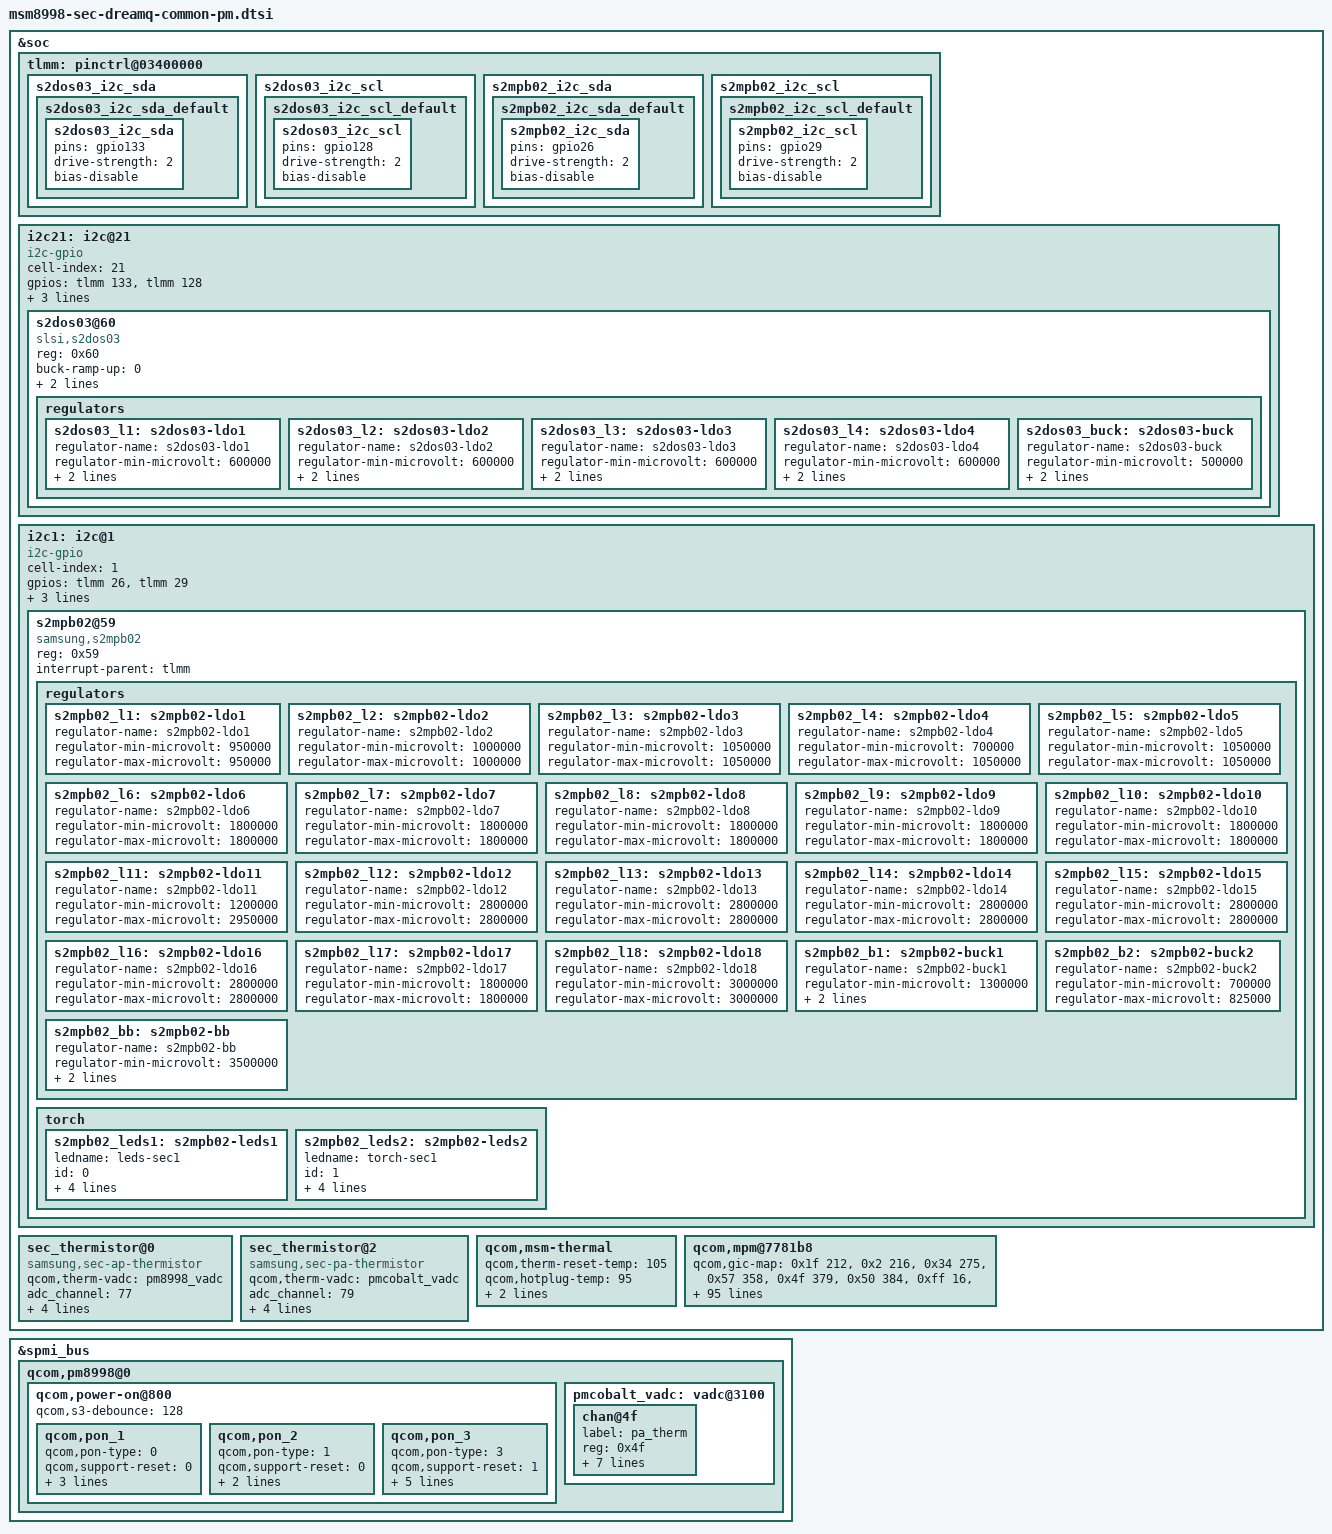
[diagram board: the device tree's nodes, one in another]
/* Copyright (c) 2014, The Linux Foundation. All rights reserved.
 *
 * This program is free software; you can redistribute it and/or modify
 * it under the terms of the GNU General Public License version 2 and
 * only version 2 as published by the Free Software Foundation.
 *
 * This program is distributed in the hope that it will be useful,
 * but WITHOUT ANY WARRANTY; without even the implied warranty of
 * MERCHANTABILITY or FITNESS FOR A PARTICULAR PURPOSE.  See the
 * GNU General Public License for more details.
 */

&soc {
	tlmm: pinctrl@03400000 {
		s2dos03_i2c_sda {
			s2dos03_i2c_sda_default: s2dos03_i2c_sda_default {
				s2dos03_i2c_sda {
					pins = "gpio133";
					drive-strength = <2>;
					bias-disable;
				};
			};
		};
		s2dos03_i2c_scl {
			s2dos03_i2c_scl_default: s2dos03_i2c_scl_default {
				s2dos03_i2c_scl {
					pins = "gpio128";
					drive-strength = <2>;
					bias-disable;
				};
			};
		};

		s2mpb02_i2c_sda {
			s2mpb02_i2c_sda_default: s2mpb02_i2c_sda_default {
				s2mpb02_i2c_sda {
					pins = "gpio26";
					drive-strength = <2>;
					bias-disable;
				};
			};
		};
		s2mpb02_i2c_scl {
			s2mpb02_i2c_scl_default: s2mpb02_i2c_scl_default {
				s2mpb02_i2c_scl {
					pins = "gpio29";
					drive-strength = <2>;
					bias-disable;
				};
			};
		};
	};

	/* S2DOS03 Display PMIC */
	i2c21: i2c@21 {
		cell-index = <21>;
		compatible = "i2c-gpio";
		gpios = <&tlmm 133 0 /* sda */
			&tlmm 128 0 /* scl */
		>;
		#i2c-gpio,delay-us = <2>;
		#address-cells = <1>;
		#size-cells = <0>;

		pinctrl-names = "s2dos03_i2c_pins_default";
		pinctrl-0 = <&s2dos03_i2c_sda_default &s2dos03_i2c_scl_default>;

		s2dos03@60 {
			compatible = "slsi,s2dos03";
			reg = <0x60>;

			buck-ramp-up = <0>;		/* 6.25mV/us */
			buck-fpwm = <0>;		/* Disable */

			uvlo-fall-threshold = <0>;	/* 2.30V */

			regulators {
				s2dos03_l1: s2dos03-ldo1 {
					regulator-name = "s2dos03-ldo1";
					regulator-min-microvolt = <600000>;
					regulator-max-microvolt = <3775000>;
					active-discharge-enable = <1>;
				};

				s2dos03_l2: s2dos03-ldo2 {
					regulator-name = "s2dos03-ldo2";
					regulator-min-microvolt = <600000>;
					regulator-max-microvolt = <3775000>;
					active-discharge-enable = <1>;
				};

				s2dos03_l3: s2dos03-ldo3 {
					regulator-name = "s2dos03-ldo3";
					regulator-min-microvolt = <600000>;
					regulator-max-microvolt = <3775000>;
					active-discharge-enable = <1>;
				};

				s2dos03_l4: s2dos03-ldo4 {
					regulator-name = "s2dos03-ldo4";
					regulator-min-microvolt = <600000>;
					regulator-max-microvolt = <3775000>;
					active-discharge-enable = <1>;
				};

				s2dos03_buck: s2dos03-buck {
					regulator-name = "s2dos03-buck";
					regulator-min-microvolt = <500000>;
					regulator-max-microvolt = <2093750>;
					active-discharge-enable = <1>;
				};
			};
		};
	};

	/* S2MPB02 Camera PMIC */
	i2c1: i2c@1 {
		cell-index = <1>;
		compatible = "i2c-gpio";
		gpios = <&tlmm 26 0
			&tlmm 29 0
		>;
		i2c-gpio,delay-us = <2>;
		#address-cells = <1>;
		#size-cells = <0>;

		pinctrl-names = "default";
		pinctrl-0 = <&s2mpb02_i2c_sda_default &s2mpb02_i2c_scl_default>;

		s2mpb02@59 {
			compatible = "samsung,s2mpb02";
			reg = <0x59>;
			interrupt-parent = <&tlmm>;
			status = "okay";

			regulators {
				s2mpb02_l1: s2mpb02-ldo1 {
					regulator-name = "s2mpb02-ldo1";
					regulator-min-microvolt = <950000>;
					regulator-max-microvolt = <950000>;
				};

				s2mpb02_l2: s2mpb02-ldo2 {
					regulator-name = "s2mpb02-ldo2";
					regulator-min-microvolt = <1000000>;
					regulator-max-microvolt = <1000000>;
				};

				s2mpb02_l3: s2mpb02-ldo3 {
					regulator-name = "s2mpb02-ldo3";
					regulator-min-microvolt = <1050000>;
					regulator-max-microvolt = <1050000>;
				};

				s2mpb02_l4: s2mpb02-ldo4 {
					regulator-name = "s2mpb02-ldo4";
					regulator-min-microvolt = <700000>;
					regulator-max-microvolt = <1050000>;
				};

				s2mpb02_l5: s2mpb02-ldo5 {
					regulator-name = "s2mpb02-ldo5";
					regulator-min-microvolt = <1050000>;
					regulator-max-microvolt = <1050000>;
				};

				s2mpb02_l6: s2mpb02-ldo6 {
					regulator-name = "s2mpb02-ldo6";
					regulator-min-microvolt = <1800000>;
					regulator-max-microvolt = <1800000>;
				};

				s2mpb02_l7: s2mpb02-ldo7 {
					regulator-name = "s2mpb02-ldo7";
					regulator-min-microvolt = <1800000>;
					regulator-max-microvolt = <1800000>;
				};

				s2mpb02_l8: s2mpb02-ldo8 {
					regulator-name = "s2mpb02-ldo8";
					regulator-min-microvolt = <1800000>;
					regulator-max-microvolt = <1800000>;
				};

				s2mpb02_l9: s2mpb02-ldo9 {
					regulator-name = "s2mpb02-ldo9";
					regulator-min-microvolt = <1800000>;
					regulator-max-microvolt = <1800000>;
				};

				s2mpb02_l10: s2mpb02-ldo10 {
					regulator-name = "s2mpb02-ldo10";
					regulator-min-microvolt = <1800000>;
					regulator-max-microvolt = <1800000>;
				};

				s2mpb02_l11: s2mpb02-ldo11 {
					regulator-name = "s2mpb02-ldo11";
					regulator-min-microvolt = <1200000>;
					regulator-max-microvolt = <2950000>;
				};

				s2mpb02_l12: s2mpb02-ldo12 {
					regulator-name = "s2mpb02-ldo12";
					regulator-min-microvolt = <2800000>;
					regulator-max-microvolt = <2800000>;
				};

				s2mpb02_l13: s2mpb02-ldo13 {
					regulator-name = "s2mpb02-ldo13";
					regulator-min-microvolt = <2800000>;
					regulator-max-microvolt = <2800000>;
				};

				s2mpb02_l14: s2mpb02-ldo14 {
					regulator-name = "s2mpb02-ldo14";
					regulator-min-microvolt = <2800000>;
					regulator-max-microvolt = <2800000>;
				};

				s2mpb02_l15: s2mpb02-ldo15 {
					regulator-name = "s2mpb02-ldo15";
					regulator-min-microvolt = <2800000>;
					regulator-max-microvolt = <2800000>;
				};

				s2mpb02_l16: s2mpb02-ldo16 {
					regulator-name = "s2mpb02-ldo16";
					regulator-min-microvolt = <2800000>;
					regulator-max-microvolt = <2800000>;
				};

				s2mpb02_l17: s2mpb02-ldo17 {
					regulator-name = "s2mpb02-ldo17";
					regulator-min-microvolt = <1800000>;
					regulator-max-microvolt = <1800000>;
				};

				s2mpb02_l18: s2mpb02-ldo18 {
					regulator-name = "s2mpb02-ldo18";
					regulator-min-microvolt = <3000000>;
					regulator-max-microvolt = <3000000>;
				};

				s2mpb02_b1: s2mpb02-buck1 {
					regulator-name = "s2mpb02-buck1";
					regulator-min-microvolt = <1300000>;
					regulator-max-microvolt = <1300000>;
					regulator-always-on;
				};

				s2mpb02_b2: s2mpb02-buck2 {
					regulator-name = "s2mpb02-buck2";
					regulator-min-microvolt = <700000>;
					regulator-max-microvolt = <825000>;
				};

				s2mpb02_bb: s2mpb02-bb {
					regulator-name = "s2mpb02-bb";
					regulator-min-microvolt = <3500000>;
					regulator-max-microvolt = <3500000>;
					regulator-always-on;
				};
			};

			torch {
				status = "okay";
				s2mpb02_leds1: s2mpb02-leds1 {
					ledname = "leds-sec1";
					/* S2MPB02_FLASH_LED_1 */
					id = <0>;
					/* S2MPB02_FLASH_CURRENT */
					brightness = <0xA>;
					/* S2MPB02_FLASH_TIMEOUT */
					timeout = <0x7>;
					default-trigger = "flash_trigger";
					gpios = <&tlmm 22 0>;
				};

				s2mpb02_leds2: s2mpb02-leds2 {
					ledname = "torch-sec1";
					/* S2MPB02_TORCH_LED_1 */
					id = <1>;
					/* S2MPB02_TORCH_CURRENT */
					brightness = <0x9>;
					/* S2MPB02_TORCH_TIMEOUT */
					timeout = <0xF>;
					default-trigger = "torch_trigger";
					gpios = <&tlmm 21 0>;
				};
			};
		};
	};

	/* Thermistor table */
	sec_thermistor@0 {
		compatible = "samsung,sec-ap-thermistor";
		qcom,therm-vadc = <&pm8998_vadc>;
		status = "okay";
		adc_channel = <77>;
		adc_array = <1002 1039 1076 1112 1149 1186 1236 1286 1335 1385
				  	 1435 1487 1540 1592 1645 1697 1760 1823 1886 1949
					 2012 2085 2157 2230 2302 2375 2482 2589 2696 2803
					 2910 3035 3159 3284 3408 3533 3649 3765 3881 3997
					 4113 4246 4379 4513 4646 4779 4928 5077 5227 5376
					 5525 5691 5857 6023 6189 6355 6528 6700 6873 7045
					 7218 7398 7578 7757 7937 8117 8305 8492 8680 8867
					 9055 9224 9392 9561 9729 9898 10092 10287 10481 10676
					 10870 11035 11200 11365 11530 11695 11859 12024 12188 12353
					 12517 12656 12795 12935 13074 13213 13341 13469 13596 13724
					 13852 13962 14071 14181 14290 14400 14490 14580 14670 14760
					 14850>;

		temp_array = <900 890 880 870 860 850 840 830 820 810
				800 790 780 770 760 750 740 730 720 710
				700 690 680 670 660 650 640 630 620 610
				600 590 580 570 560 550 540 530 520 510
				500 490 480 470 460 450 440 430 420 410
				400 390 380 370 360 350 340 330 320 310
				300 290 280 270 260 250 240 230 220 210
				200 190 180 170 160 150 140 130 120 110
				100 90 80 70 60 50 40 30 20 10
				0
				(-10) (-20) (-30) (-40) (-50) (-60) (-70) (-80) (-90) (-100)
				(-110)(-120)(-130)(-140)(-150)(-160)(-170)(-180)(-190) (-200)>;
	};

	/* PA Thermistor table */
	sec_thermistor@2 {
		compatible = "samsung,sec-pa-thermistor";
		qcom,therm-vadc = <&pmcobalt_vadc>;
		status = "okay";
		adc_channel = <79>;
		adc_array = <1002 1039 1076 1112 1149 1186 1236 1286 1335 1385
				  	 1435 1487 1540 1592 1645 1697 1760 1823 1886 1949
					 2012 2085 2157 2230 2302 2375 2482 2589 2696 2803
					 2910 3035 3159 3284 3408 3533 3649 3765 3881 3997
					 4113 4246 4379 4513 4646 4779 4928 5077 5227 5376
					 5525 5691 5857 6023 6189 6355 6528 6700 6873 7045
					 7218 7398 7578 7757 7937 8117 8305 8492 8680 8867
					 9055 9224 9392 9561 9729 9898 10092 10287 10481 10676
					 10870 11035 11200 11365 11530 11695 11859 12024 12188 12353
					 12517 12656 12795 12935 13074 13213 13341 13469 13596 13724
					 13852 13962 14071 14181 14290 14400 14490 14580 14670 14760
					 14850>;

		temp_array = <900 890 880 870 860 850 840 830 820 810
				800 790 780 770 760 750 740 730 720 710
				700 690 680 670 660 650 640 630 620 610
				600 590 580 570 560 550 540 530 520 510
				500 490 480 470 460 450 440 430 420 410
				400 390 380 370 360 350 340 330 320 310
				300 290 280 270 260 250 240 230 220 210
				200 190 180 170 160 150 140 130 120 110
				100 90 80 70 60 50 40 30 20 10
				0
				(-10) (-20) (-30) (-40) (-50) (-60) (-70) (-80) (-90) (-100)
				(-110)(-120)(-130)(-140)(-150)(-160)(-170)(-180)(-190) (-200)>;
	};

	qcom,msm-thermal {
		qcom,therm-reset-temp = <105>;
		qcom,hotplug-temp = <95>;
		sec,therm-reset-temp-offset = <10>;
		sec,hotplug-temp-offset = <10>;
	};

	qcom,mpm@7781b8 {
			qcom,gic-map =
			<0x1f 212>, /* usb30_power_event_irq	*/
			<0x2 216>, /* tsens1_upper_lower_int	*/
			<0x34 275>, /* qmp_usb3_lfps_rxterm_irq_cx	*/
			<0x57 358>, /*  spmi_periph_irq[0]	*/
			<0x4f 379>, /* usb2phy_intr	*/
			<0x50 384>, /* sp_rmb_sp2soc_irq	*/
			<0xff 16>, /* APC0_qgicQTmrHypPhysIrptReq	*/
			<0xff 17>, /* APC3_qgicQTmrSecPhysIrptReq	*/
			<0xff 18>, /* APC0_qgicQTmrNonSecPhysIrptReq	*/
			<0xff 19>, /* APC3_qgicQTmrVirtIrptReq	*/
			<0xff 20>, /* APC0_dbgCommRxFull	*/
			<0xff 21>, /* APC3_dbgCommTxEmpty	*/
			<0xff 22>, /* APC0_qgicPerfMonIrptReq	*/
			<0xff 23>, /* corespm_vote_int[7]	*/
			<0xff 24>, /* APC0_qgicExtFaultIrptReq	*/
			<0xff 28>, /* qgicWakeupSync	*/
			<0xff 29>, /* APCC_cti_SPI_intx	*/
			<0xff 30>, /* APCC_cti_SPI_inty	*/
			<0xff 32>, /* l2spm_vote_int[0]	*/
			<0xff 33>, /* l2spm_vote_int[1]	*/
			<0xff 34>, /* APCC_qgicL2ErrorIrptReq	*/
			<0xff 35>, /* WDT_barkInt	*/
			<0xff 36>, /* WDT_biteExpired	*/
			<0xff 39>, /* QTMR_qgicFrm0VirtIrq	*/
			<0xff 40>, /* QTMR_qgicFrm0PhyIrq	*/
			<0xff 41>, /* QTMR_qgicFrm1PhyIrq	*/
			<0xff 42>, /* QTMR_qgicFrm2PhyIrq	*/
			<0xff 43>, /* QTMR_qgicFrm3PhyIrq	*/
			<0xff 44>, /* QTMR_qgicFrm4PhyIrq	*/
			<0xff 45>, /* QTMR_qgicFrm5PhyIrq	*/
			<0xff 46>, /* QTMR_qgicFrm6PhyIrq	*/
			<0xff 47>, /* rbif_Irq[0]	*/
			<0xff 48>, /* rbif_Irq[1]	*/
			<0xff 52>, /* cci_spm_vote_summary_int	*/
			<0xff 54>, /* ~nERRORIRQ	*/
			<0xff 55>, /* nEVNTCNTOVERFLOW_cci	*/
			<0xff 56>, /* QTMR_qgicFrm0VirtIrq	*/
			<0xff 57>, /* QTMR_qgicFrm0PhyIrq	*/
			<0xff 58>, /* QTMR_qgicFrm1PhyIrq	*/
			<0xff 59>, /* QTMR_qgicFrm2PhyIrq	*/
			<0xff 60>, /* QTMR_qgicFrm3PhyIrq	*/
			<0xff 61>, /* QTMR_qgicFrm4PhyIrq	*/
			<0xff 62>, /* QTMR_qgicFrm5PhyIrq	*/
			<0xff 63>, /* QTMR_qgicFrm6PhyIrq	*/
			<0xff 64>, /* wakeup_counter_irq_OR	*/
			<0xff 65>, /* apc0_vs_alarm	*/
			<0xff 66>, /* apc1_vs_alarm	*/
			<0xff 67>, /* o_pwr_osm_irq	*/
			<0xff 68>, /* o_perf_osm_irq	*/
			<0xff 69>, /* o_pwr_dcvsh_interrupt	*/
			<0xff 70>, /* o_perf_dcvsh_interrupt	*/
			<0xff 73>, /* L2_EXTERRIRQ_C0	*/
			<0xff 74>, /* L2_EXTERRIRQ_C1	*/
			<0xff 75>, /* L2_INTERRIRQ_C0	*/
			<0xff 76>, /* L2_INTERRIRQ_C1	*/
			<0xff 77>, /* L2SPM_svicInt[0]	*/
			<0xff 78>, /* L2SPM_svicInt[1]	*/
			<0xff 79>, /* L2SPM_svicIntSwDone[0]	*/
			<0xff 80>, /* L2SPM_svicIntSwDone[1]	*/
			<0xff 81>, /* l2_avs_err[0]	*/
			<0xff 82>, /* l2_avs_err[1]	*/
			<0xff 83>, /* l2_avs_ack[0]	*/
			<0xff 84>, /* l2_avs_ack[1]	*/
			<0xff 96>, /* uart_dm_intr	*/
			<0xff 97>, /* uart_dm_intr	*/
			<0xff 98>, /* o_qm_interrupt	*/
			<0xff 100>, /* jpeg_vbif_irpt	*/
			<0xff 101>, /* processor_1_user_int	*/
			<0xff 102>, /* processor_1_kernel_int	*/
			<0xff 106>, /* dir_conn_irq_lpa_dsp_2	*/
			<0xff 107>, /* dir_conn_irq_lpa_dsp_1	*/
			<0xff 109>, /* camss_vbif_0_irq	*/
			<0xff 110>, /* csiphy_irq	*/
			<0xff 111>, /* csiphy_irq	*/
			<0xff 112>, /* csiphy_irq	*/
			<0xff 115>, /* mdp_irq	*/
			<0xff 116>, /* vbif_irpt	*/
			<0xff 117>, /* dir_conn_irq_lpa_dsp_0	*/
			<0xff 119>, /* lcc_audio_wrapper_q6	*/
			<0xff 122>, /* PIMEM TPDM BC interrupt	*/
			<0xff 123>, /* PIMEM TPDM TC interrupt	*/
			<0xff 124>, /* dir_conn_irq_sensors_1	*/
			<0xff 125>, /* dir_conn_irq_sensors_0	*/
			<0xff 126>, /* qup_irq	*/
			<0xff 127>, /* qup_irq	*/
			<0xff 128>, /* qup_irq	*/
			<0xff 129>, /* qup_irq	*/
			<0xff 130>, /* qup_irq	*/
			<0xff 131>, /* qup_irq	*/
			<0xff 132>, /* qup_irq	*/
			<0xff 133>, /* qup_irq	*/
			<0xff 134>, /* qup_irq	*/
			<0xff 135>, /* qup_irq	*/
			<0xff 136>, /* qup_irq	*/
			<0xff 137>, /* qup_irq	*/
			<0xff 138>, /* qup_irq	*/
			<0xff 139>, /* uart_dm_intr	*/
			<0xff 140>, /* uart_dm_intr	*/
			<0xff 141>, /* uart_dm_intr	*/
			<0xff 145>, /* uart_dm_intr	*/
			<0xff 146>, /* uart_dm_intr	*/
			<0xff 147>, /* uart_dm_intr	*/
			<0xff 148>, /* osmmu_Cirpt[4]	*/
			<0xff 149>, /* osmmu_Cirpt[5]	*/
			<0xff 151>, /* tsif_irq[0]	*/
			<0xff 152>, /* tsif_irq[1]	*/
			<0xff 153>, /* tspp_irq	*/
			<0xff 154>, /* bam_irq	*/
			<0xff 155>, /* dir_conn_irq_lpa_dsp_5	*/
			<0xff 156>, /* dir_conn_irq_lpa_dsp_4	*/
			<0xff 157>, /* sdcc_irq	*/
			<0xff 158>, /* sdcc_irq	*/
			<0xff 159>, /* lpass_qos_apps_interrupt	*/
			<0xff 160>, /* smmu_PMIrpt	*/
			<0xff 161>, /* sdcc_irq	*/
			<0xff 162>, /* sdcc_irq	*/
			<0xff 163>, /* usb30_ctrl_irq[0]	*/
			<0xff 164>, /* usb30_bam_irq	*/
			<0xff 165>, /* usb30_hs_phy_irq	*/
			<0xff 166>, /* o_lm_int_2qgic	*/
			<0xff 167>, /* pcie20_inta	*/
			<0xff 168>, /* pcie20_intb	*/
			<0xff 169>, /* smmu_Cirpt[12]	*/
			<0xff 170>, /* pcie20_intc	*/
			<0xff 171>, /* pcie20_intd	*/
			<0xff 172>, /* dcvs_int(8)	*/
			<0xff 173>, /* dcvs_int(9)	*/
			<0xff 184>, /* dir_conn_irq_lpa_dsp_3	*/
			<0xff 185>, /* camss_vbif_2_irq	*/
			<0xff 186>, /* mnoc_obs_mainFault	*/
			<0xff 188>, /* q6ss_irq_out(4)	*/
			<0xff 189>, /* q6ss_irq_out(5)	*/
			<0xff 190>, /* q6ss_irq_out(6)	*/
			<0xff 191>, /* q6ss_irq_out(7)	*/
			<0xff 192>, /* audio_out0_irq	*/
			<0xff 194>, /* q6ss_wdog_exp_irq	*/
			<0xff 195>, /* lpass_slimbus_core_ee1_irq	*/
			<0xff 196>, /* lpass_slimbus_bam_ee1_irq	*/
			<0xff 197>, /* resampler_irq[0]	*/
			<0xff 199>, /* qdss_usb_trace_bam_irq	*/
			<0xff 200>, /* rpm_ipc[4]	*/
			<0xff 201>, /* rpm_ipc[5]	*/
			<0xff 202>, /* rpm_ipc[6]	*/
			<0xff 203>, /* rpm_ipc[7]	*/
			<0xff 204>, /* rpm_ipc[20]	*/
			<0xff 205>, /* rpm_ipc[21]	*/
			<0xff 206>, /* rpm_ipc[22]	*/
			<0xff 207>, /* rpm_ipc[23]	*/
			<0xff 208>, /* q6ss_irq_out(4)	*/
			<0xff 209>, /* q6ss_irq_out(5)	*/
			<0xff 210>, /* q6ss_irq_out(6)	*/
			<0xff 211>, /* q6ss_irq_out(7)	*/
			<0xff 213>, /* secure_wdog_bark_irq	*/
			<0xff 214>, /* tsens1_tsens_max_min_int	*/
			<0xff 215>, /* o_bimc_intr[0]	*/
			<0xff 217>, /* ocimem_nonsec_irq	*/
			<0xff 218>, /* sscaon_tmr_timeout_irq	*/
			<0xff 219>, /* q6ss_irq_out(28)	*/
			<0xff 220>, /* spmi_protocol_irq	*/
			<0xff 221>, /* q6ss_irq_out(29)	*/
			<0xff 222>, /* q6ss_irq_out(30)	*/
			<0xff 223>, /* spdm_offline_irq	*/
			<0xff 224>, /* spdm_realtime_irq	*/
			<0xff 225>, /* snoc_obs_mainFault	*/
			<0xff 226>, /* cnoc_obs_mainFault	*/
			<0xff 227>, /* o_ss_xpu3_sec_intr	*/
			<0xff 228>, /* o_tcsr_xpu3_non_sec_summary_intr	*/
			<0xff 229>, /* o_timeout_slave_kpss_summary_intr */
			<0xff 230>, /* o_tcsr_vmidmt_client_sec_summary_intr */
			<0xff 231>, /* o_tcsr_vmidmt_client_non_sec */
			<0xff 232>, /* o_tcsr_vmidmt_cfg_sec_summary_intr */
			<0xff 233>, /* o_tcsr_vmidmt_cfg_non_sec */
			<0xff 234>, /* q6ss_irq_out(31)	*/
			<0xff 235>, /* cpr_irq[0]	*/
			<0xff 236>, /* crypto_core_irq[0]	*/
			<0xff 237>, /* crypto_core_irq[1]	*/
			<0xff 238>, /* crypto_bam_irq[0]	*/
			<0xff 239>, /* crypto_bam_irq[1]	*/
			<0xff 240>, /* summary_irq_hmss	*/
			<0xff 241>, /* dir_conn_irq_hmss_7	*/
			<0xff 242>, /* dir_conn_irq_hmss_6	*/
			<0xff 243>, /* dir_conn_irq_hmss_5	*/
			<0xff 244>, /* dir_conn_irq_hmss_4	*/
			<0xff 245>, /* dir_conn_irq_hmss_3	*/
			<0xff 246>, /* dir_conn_irq_hmss_2	*/
			<0xff 247>, /* dir_conn_irq_hmss_1	*/
			<0xff 248>, /* dir_conn_irq_hmss_0	*/
			<0xff 249>, /* summary_irq_hmss_tz	*/
			<0xff 250>, /* cpr_irq[3]	*/
			<0xff 251>, /* cpr_irq[2]	*/
			<0xff 252>, /* cpr_irq[1]	*/
			<0xff 253>, /* sdcc_pwr_cmd_irq	*/
			<0xff 254>, /* sdio_wakeup_irq	*/
			<0xff 255>, /* cpr_irq[0]	*/
			<0xff 256>, /* smmu_Cirpt[13]	*/
			<0xff 257>, /* smmu_Cirpt[14]	*/
			<0xff 258>, /* smmu_Cirpt[0]	*/
			<0xff 259>, /* sdcc_pwr_cmd_irq	*/
			<0xff 260>, /* sdio_wakeup_irq	*/
			<0xff 261>, /* o_tcsr_mmu_nsgcfglrpt_summary_intr */
			<0xff 262>, /* o_tcsr_mmu_gcfglrpt_summary_intr	*/
			<0xff 263>, /* o_tcsr_mmu_nsglrpt_summary_intr	*/
			<0xff 264>, /* o_tcsr_mmu_glrpt_summary_intr	*/
			<0xff 265>, /* vbif_irpt	*/
			<0xff 266>, /* smmu_PMIrpt	*/
			<0xff 267>, /* smmu_Cirpt[3]	*/
			<0xff 268>, /* q6ss_irq_out(31)	*/
			<0xff 269>, /* rpm_wdog_expired_irq	*/
			<0xff 270>, /* bam_irq	*/
			<0xff 271>, /* bam_irq	*/
			<0xff 272>, /* q6ss_irq_out(28)	*/
			<0xff 273>, /* q6ss_irq_out(29)	*/
			<0xff 274>, /* q6ss_irq_out(30)	*/
			<0xff 276>, /* osmmu_Cirpt [4]	*/
			<0xff 277>, /* osmmu_Cirpt [5]	*/
			<0xff 278>, /* usb30_ctrl_irq[1]	*/
			<0xff 279>, /* osmmu_Cirpt [6]	*/
			<0xff 280>, /* osmmu_Cirpt [7]	*/
			<0xff 281>, /* osmmu_Cirpt [8]	*/
			<0xff 282>, /* osmmu_Cirpt [9]	*/
			<0xff 283>, /* osmmu_Cirpt [10]	*/
			<0xff 284>, /* osmmu_Cirpt [11]	*/
			<0xff 285>, /* osmmu_Cirpt [12]	*/
			<0xff 286>, /* osmmu_Cirpt [13]	*/
			<0xff 287>, /* osmmu_Cirpt [14]	*/
			<0xff 288>, /* osmmu_Cirpt [15]	*/
			<0xff 289>, /* ufs_ice_sec_level_irq	*/
			<0xff 290>, /* cpr_irq[4]	*/
			<0xff 291>, /* smmu_Cirpt[2]	*/
			<0xff 292>, /* osmmu_Cirpt [16]	*/
			<0xff 293>, /* osmmu_Cirpt [17]	*/
			<0xff 294>, /* osmmu_Cirpt [18]	*/
			<0xff 295>, /* osmmu_Cirpt [0]	*/
			<0xff 296>, /* osmmu_PMIrpt	*/
			<0xff 297>, /* ufs_intrq	*/
			<0xff 298>, /* osmmu_Cirpt [1]	*/
			<0xff 299>, /* osmmu_Cirpt [2]	*/
			<0xff 300>, /* osmmu_Cirpt [3]	*/
			<0xff 301>, /* smmu_Cirpt[1]	*/
			<0xff 302>, /* qdss_etrbytecnt_irq	*/
			<0xff 303>, /* smmu_Cirpt[0]	*/
			<0xff 304>, /* osmmu_Cirpt [19]	*/
			<0xff 305>, /* osmmu_Cirpt [20]	*/
			<0xff 306>, /* osmmu_Cirpt [21]	*/
			<0xff 307>, /* osmmu_Cirpt [22]	*/
			<0xff 308>, /* osmmu_Cirpt [23]	*/
			<0xff 310>, /* pcie20_global_int	*/
			<0xff 311>, /* pcie20_int_edma_int	*/
			<0xff 316>, /* lpass_hdmitx_interrupt_ext	*/
			<0xff 317>, /* rbif_irq	*/
			<0xff 318>, /* gpu_cc_gpu_cx_gds_hw_ctrl_irq_out */
			<0xff 319>, /* VENUS_IRQ	*/
			<0xff 323>, /* lpass_slimbus1_core_ee1_irq	*/
			<0xff 324>, /* lpass_slimbus1_bam_ee1_irq	*/
			<0xff 325>, /* camss_irq18	*/
			<0xff 326>, /* camss_irq0	*/
			<0xff 327>, /* camss_irq1	*/
			<0xff 328>, /* camss_irq2	*/
			<0xff 329>, /* camss_irq3	*/
			<0xff 330>, /* camss_irq4	*/
			<0xff 331>, /* camss_irq5	*/
			<0xff 332>, /* GC_SYS_irq_0	*/
			<0xff 333>, /* GC_SYS_irq_1	*/
			<0xff 334>, /* GC_SYS_irq_2	*/
			<0xff 335>, /* GC_SYS_irq_3	*/
			<0xff 336>, /* camss_irq13	*/
			<0xff 337>, /* camss_irq14	*/
			<0xff 338>, /* camss_irq15	*/
			<0xff 339>, /* camss_irq16	*/
			<0xff 340>, /* camss_irq17	*/
			<0xff 341>, /* camss_irq6	*/
			<0xff 342>, /* smmu_Cirpt[15]	*/
			<0xff 343>, /* bam_irq[0]	*/
			<0xff 344>, /* uart_dm_intr	*/
			<0xff 345>, /* camss_irq7	*/
			<0xff 346>, /* camss_irq8	*/
			<0xff 347>, /* camss_irq9	*/
			<0xff 348>, /* camss_irq10	*/
			<0xff 350>, /* camss_irq12	*/
			<0xff 351>, /* sif_aud_dec_out_irq_ext	*/
			<0xff 356>, /* vbif_nrt_irpt	*/
			<0xff 357>, /* Nonfatal pIMEM interrupt	*/
			<0xff 359>, /* spmi_periph_irq[1]	*/
			<0xff 360>, /* fatal pIMEM interrupt	*/
			<0xff 361>, /* osmmu_Cirpt[0]	*/
			<0xff 362>, /* osmmu_Cirpt[1]	*/
			<0xff 363>, /* osmmu_Cirpt[2]	*/
			<0xff 364>, /* osmmu_Cirpt[3]	*/
			<0xff 365>, /* ipa_irq(0)	*/
			<0xff 366>, /* osmmu_PMIrpt	*/
			<0xff 380>, /* sp_sp2apps_irq[0]	*/
			<0xff 381>, /* sp_sp2apps_irq[1]	*/
			<0xff 382>, /* sp_sp2apps_irq[2]	*/
			<0xff 383>, /* sp_sp2apps_irq[3]	*/
			<0xff 385>, /* osmmu_CIrpt[12]	*/
			<0xff 386>, /* osmmu_CIrpt[13]	*/
			<0xff 387>, /* osmmu_CIrpt[14]	*/
			<0xff 388>, /* osmmu_CIrpt[15]	*/
			<0xff 389>, /* osmmu_CIrpt[16]	*/
			<0xff 390>, /* osmmu_CIrpt[17]	*/
			<0xff 391>, /* osmmu_CIrpt[18]	*/
			<0xff 392>, /* osmmu_CIrpt[19]	*/
			<0xff 393>, /* o_dcc_crc_fail_int	*/
			<0xff 395>, /* aggre1_obs_mainfault	*/
			<0xff 396>, /* aggr1_smmu_cirpt[0]	*/
			<0xff 397>, /* aggr1_smmu_cirpt[1]	*/
			<0xff 398>, /* aggr1_smmu_cirpt[2]	*/
			<0xff 399>, /* aggr1_smmu_cirpt[3]	*/
			<0xff 400>, /* aggr1_smmu_cirpt[4]	*/
			<0xff 401>, /* aggr1_smmu_cirpt[5]	*/
			<0xff 402>, /* aggr1_smmu_cirpt[6]	*/
			<0xff 403>, /* aggr1_smmu_pmirpt	*/
			<0xff 404>, /* aggre2noc_obs_mainFault	*/
			<0xff 405>, /* osmmu_CIrpt[0]	*/
			<0xff 406>, /* osmmu_CIrpt[1]	*/
			<0xff 407>, /* osmmu_CIrpt[2]	*/
			<0xff 408>, /* osmmu_CIrpt[3]	*/
			<0xff 409>, /* osmmu_CIrpt[4]	*/
			<0xff 410>, /* osmmu_CIrpt[5]	*/
			<0xff 411>, /* o_dcc_task_done_int	*/
			<0xff 412>, /* vsense_alarm_irq	*/
			<0xff 413>, /* osmmu_PMIrpt	*/
			<0xff 414>, /* pmic_arb_trans_done_irq[0]	*/
			<0xff 415>, /* pmic_arb_trans_done_irq[1]	*/
			<0xff 416>, /* rpm_ipc[28]	*/
			<0xff 417>, /* rpm_ipc[29]	*/
			<0xff 418>, /* rpm_ipc[30]	*/
			<0xff 419>, /* rpm_ipc[31]	*/
			<0xff 420>, /* qup_irq	*/
			<0xff 421>, /* qup_irq	*/
			<0xff 422>, /* wd_bite_apps	*/
			<0xff 423>, /* lpass_qos_apps_interrupt	*/
			<0xff 424>, /* ipa_irq(2)	*/
			<0xff 425>, /* smmu_Cirpt[1]	*/
			<0xff 426>, /* smmu_Cirpt[2]	*/
			<0xff 427>, /* smmu_Cirpt[3]	*/
			<0xff 428>, /* smmu_Cirpt[4]	*/
			<0xff 429>, /* smmu_Cirpt[5]	*/
			<0xff 430>, /* smmu_Cirpt[6]	*/
			<0xff 431>, /* smmu_Cirpt[7]	*/
			<0xff 432>, /* smmu_Cirpt[8]	*/
			<0xff 433>, /* smmu_Cirpt[9]	*/
			<0xff 434>, /* smmu_Cirpt[10]	*/
			<0xff 435>, /* smmu_Cirpt[11]	*/
			<0xff 436>, /* smmu_Cirpt[16]	*/
			<0xff 437>, /* pcie20_0_int_msi_dev0	*/
			<0xff 438>, /* pcie20_0_int_msi_dev1	*/
			<0xff 439>, /* pcie20_0_int_msi_dev2	*/
			<0xff 440>, /* pcie20_0_int_msi_dev3	*/
			<0xff 441>, /* pcie20_0_int_msi_dev4	*/
			<0xff 442>, /* pcie20_0_int_msi_dev5	*/
			<0xff 443>, /* pcie20_0_int_msi_dev6	*/
			<0xff 444>, /* pcie20_0_int_msi_dev7	*/
			<0xff 445>, /* o_wcss_apps_intr[0]	*/
			<0xff 446>, /* o_wcss_apps_intr[1]	*/
			<0xff 447>, /* o_wcss_apps_intr[2]	*/
			<0xff 448>, /* o_wcss_apps_intr[3]	*/
			<0xff 449>, /* o_wcss_apps_intr[4]	*/
			<0xff 450>, /* o_wcss_apps_intr[5]	*/
			<0xff 452>, /* o_wcss_apps_intr[6]	*/
			<0xff 453>, /* o_wcss_apps_intr[7]	*/
			<0xff 454>, /* o_wcss_apps_intr[8]	*/
			<0xff 455>, /* o_wcss_apps_intr[9]	*/
			<0xff 456>, /* o_wcss_apps_intr[10]	*/
			<0xff 457>, /* o_wcss_apps_intr[11]	*/
			<0xff 458>, /* o_wcss_apps_intr[12]	*/
			<0xff 461>, /* o_ocimem_nonsec_irq	*/
			<0xff 462>, /* tsens1_tsens_critical_int	*/
			<0xff 463>, /* aggr1_smmu_cirpt[7]	*/
			<0xff 464>, /* ipa_bam_irq(0)	*/
			<0xff 465>, /* ipa_bam_irq(2)	*/
			<0xff 466>, /* ssc_uart_int	*/
			<0xff 468>, /* cri_cm_irq_tz	*/
			<0xff 469>, /* cri_cm_irq_hyp	*/
			<0xff 471>, /* mmss_bimc_smmu_gds_hw_ctrl_irq_out */
			<0xff 472>, /* gcc_gds_hw_ctrl_irq_out	*/
			<0xff 473>, /* lcc_audio_core_smmu_gds_hw_ctrl */
			<0xff 477>, /* tsens0_tsens_critical_int	*/
			<0xff 478>, /* tsens0_tsens_max_min_int	*/
			<0xff 480>, /* q6ss_wdog_expired_irq	*/
			<0xff 481>, /* mss_ipc_out_irq[4]	*/
			<0xff 482>, /* mss_ipc_out_irq[5]	*/
			<0xff 483>, /* mss_ipc_out_irq[6]	*/
			<0xff 484>, /* mss_ipc_out_irq[7]	*/
			<0xff 485>, /* mss_ipc_out_irq[28]	*/
			<0xff 486>, /* mss_ipc_out_irq[29]	*/
			<0xff 487>, /* mss_ipc_out_irq[30]	*/
			<0xff 488>, /* mss_ipc_out_irq[31]	*/
			<0xff 489>, /* skl_core_irq	*/
			<0xff 490>, /* tsens0_upper_lower_int	*/
			<0xff 494>, /* osmmu_CIrpt[6]	*/
			<0xff 495>, /* osmmu_CIrpt[7]	*/
			<0xff 496>, /* osmmu_CIrpt[8]	*/
			<0xff 497>, /* osmmu_CIrpt[9]	*/
			<0xff 498>, /* osmmu_CIrpt[10]	*/
			<0xff 499>, /* osmmu_CIrpt[11]	*/
			<0xff 503>, /* o_bimc_intr[1]	*/
			<0xff 504>; /* trustonic	*/
	};
};

&spmi_bus {
	qcom,pm8998@0 {
		qcom,power-on@800 {
			qcom,s3-debounce = <128>;
			qcom,pon_1 {
				qcom,pon-type = <0>;
				qcom,support-reset = <0>;
				qcom,pull-up = <1>;
				linux,code = <116>;
				switch_powerkey;
			};

			qcom,pon_2 {
				qcom,pon-type = <1>;
				qcom,support-reset = <0>;
				qcom,pull-up = <1>;
				linux,code = <114>;
			};

			qcom,pon_3 {
				qcom,pon-type = <3>;
				qcom,support-reset = <1>;
				qcom,pull-up = <1>;
				qcom,s1-timer = <6720>;
				qcom,s2-timer = <1000>;
				qcom,s2-type = <8>;
				qcom,use-bark;
			};
		};

        pmcobalt_vadc: vadc@3100 {
            chan@4f {
                label = "pa_therm";
                reg = <0x4f>;
                qcom,decimation = <2>;
                qcom,pre-div-channel-scaling = <0>;
                qcom,calibration-type = "ratiometric";
                qcom,scale-function = <2>;
                qcom,hw-settle-time = <2>;
                qcom,fast-avg-setup = <0>;
                qcom,cal-val = <0>;
            };
        };
  	};
};
